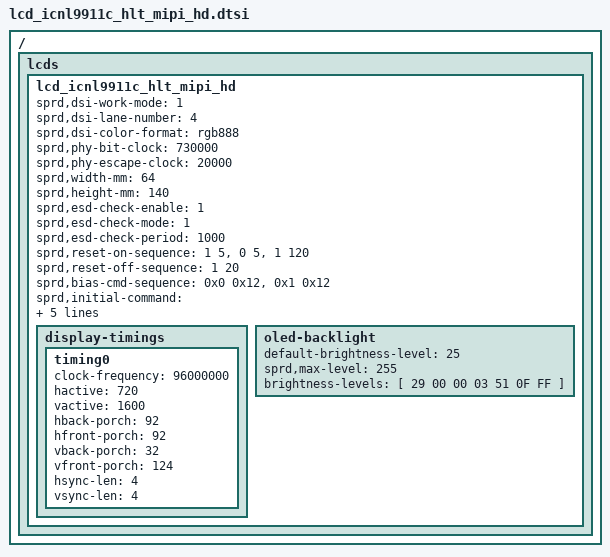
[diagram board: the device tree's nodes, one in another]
/ { lcds {
	lcd_icnl9911c_hlt_mipi_hd: lcd_icnl9911c_hlt_mipi_hd {

		sprd,dsi-work-mode = <1>;
		sprd,dsi-lane-number = <4>;
		sprd,dsi-color-format = "rgb888";

		sprd,phy-bit-clock = <730000>;
		sprd,phy-escape-clock = <20000>;

		sprd,width-mm = <64>;
		sprd,height-mm = <140>;

		sprd,esd-check-enable = <1>;
		sprd,esd-check-mode = <1>;
		sprd,esd-check-period = <1000>;

		sprd,reset-on-sequence = <1 5>, <0 5>, <1 120>;
		sprd,reset-off-sequence = <1 20>;
		sprd,bias-cmd-sequence =  <0x0 0x12>, <0x1 0x12>;
		sprd,initial-command = [
			39 00 00 03 F0 5A 59
			39 00 00 03 F1 A5 A6
			39 00 00 1F B0 82 81 05 04 87 86 84 85 66 66 33 33 20 01 01 78 01 01 0F 05 04 03 02 01 02 03 04 00 00 00
			39 00 00 1E B1 11 42 86 00 01 01 01 66 01 01 04 08 54 00 00 00 44 40 02 01 40 02 01 40 02 01 40 02 01
			39 00 00 12 B2 54 C4 82 05 40 02 01 40 02 01 05 05 54 0C 0C 0D 0B
			39 00 00 20 B3 02 00 00 00 00 26 26 91 A2 33 44 00 26 00 18 01 02 08 20 30 08 09 44 20 40 20 40 08 09 22 33
			39 00 00 1D B4 0A 02 DC 1D 00 02 02 02 02 12 10 02 02 0E 0C 04 03 03 03 03 03 03 FF FF FC 00 00 00
			39 00 00 1D B5 0B 02 DC 1D 00 02 02 02 02 13 11 02 02 0F 0D 05 03 03 03 03 03 03 FF FF FC 00 00 00
			39 00 00 19 B8 00 00 00 00 00 00 00 00 00 00 00 00 00 00 00 00 00 00 00 00 00 00 00 00
			39 00 00 0E BB 01 05 09 11 0D 19 1D 55 25 69 00 21 25
			39 00 00 0F BC 00 00 00 00 02 20 FF 00 03 33 01 73 33 00
			39 00 00 0B BD 53 12 4F CF 72 A4 08 44 AE 15
			39 00 00 0B BE 65 65 50 46 0C 77 43 07 0E 0E
			39 00 00 09 BF 07 25 07 25 7F 00 11 04
			39 00 00 0A C0 10 FF FF FF FF FF 00 FF 00
			39 00 00 14 C1 C0 20 20 7C 04 5C 5C 04 2A 40 36 00 07 CF FF FF C0 00 C0
			23 00 00 02 C2 00
			39 00 00 0A C3 06 00 FF 00 FF 00 00 81 01
			39 00 00 0C C5 03 1C C0 C0 40 10 42 44 08 09 14
			39 00 00 0B C6 87 96 2A 29 29 31 7F 34 08 04
			39 00 00 17 C7 FC B2 8B 6F 3F 1F F1 48 17 F2 CD A1 FB CF B2 88 6F 4C 1A 7E C0 00
			39 00 00 17 C8 FC B2 8B 6F 3F 1F F1 48 17 F2 CD A1 FB CF B2 88 6F 4C 1A 7E C0 00
			23 00 00 02 CB 00
			39 00 00 06 D0 80 0D FF 0F 63
			23 00 00 02 D2 42

			39 00 00 1B E0 30 00 80 88 11 3F 22 62 DF A0 04 CC 01 FF FA FF F0 FD FE FE FE F5 FC FC FB FF
			39 00 00 18 E1 BC F8 CC CC DB 9B F0 E7 F0 85 F0 70 00 00 00 9A FD F0 E0 FF 00 07 F3
			39 00 00 03 51 00 00
			23 00 00 02 53 2C
			23 00 00 02 55 03
			39 00 00 03 F1 5A 59
			39 00 00 03 F0 A5 A6
			23 00 00 02 35 00

			13 78 00 01 11
			13 32 00 01 29
			23 00 00 02 26 01
			];
		sprd,sleep-in-command = [
			23 00 00 02 26 08
			13 32 00 01 28
			13 78 00 01 10
			];
		sprd,sleep-out-command = [
			13 78 00 01 11
			13 64 00 01 29
			];

		display-timings {
			timing0 {
				clock-frequency = <96000000>;
				hactive = <720>;
				vactive = <1600>;
				hback-porch = <92>;
				hfront-porch = <92>;
				vback-porch = <32>;
				vfront-porch = <124>;
				hsync-len = <4>;
				vsync-len = <4>;
			};
		};

oled-backlight{
	default-brightness-level = <25>;
	sprd,max-level = <255>;
	brightness-levels = [
		29 00 00 03 51 0F FF
	];
};
};

};};
